AUTOSAR XML (schema 00050)
package /CalDataProvider/ComponentTypes
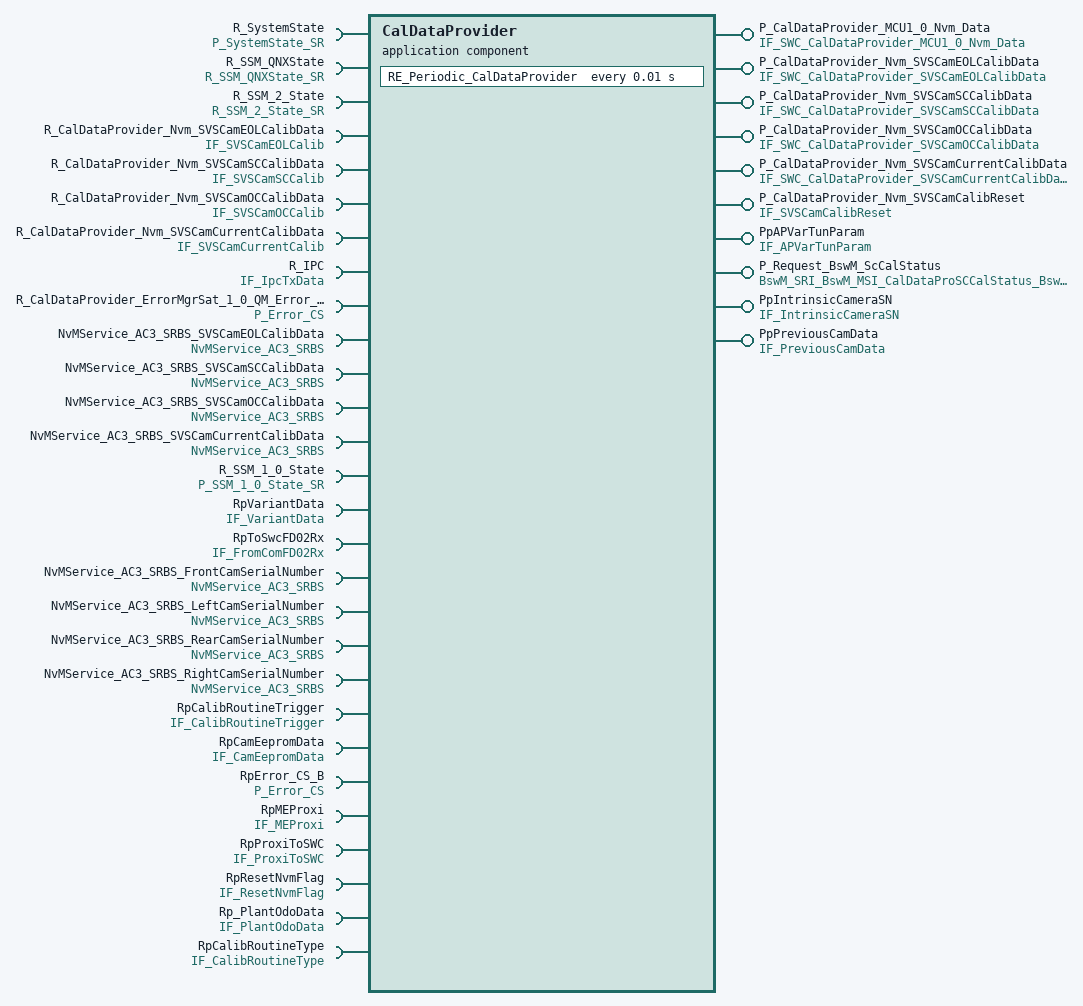
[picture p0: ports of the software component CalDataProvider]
  application sw component type CalDataProvider
    provide port P_CalDataProvider_MCU1_0_Nvm_Data: nonqueued-sender-com-spec{data-element=CalData_mcu1_0, init-value=fields=[{short-label=CalData_SVSCamCurrentCalibData, fields=[{short-label=CamFrontCurrent, fields=[{short-label=CamCalibData_STM, fields=[{short-label=calibdata, fields=[Pitch_f32:0, Yaw_f32:0, Roll_f32:0, CalibStatus_e:0, NewValueAvailable_b:0, OverwriteStatus_b:0]}, X_f32:0, Y_f32:0, Z_f32:0, EOLIterationData_au8:5 x 0, Reserved_au8:7 x 0]}, CamCalibIDs_STM:0]}, {short-label=CamLeftCurrent, fields=[{short-label=CamCalibData_STM, fields=[{short-label=calibdata, fields=[Pitch_f32:0, Yaw_f32:0, Roll_f32:0, CalibStatus_e:0, NewValueAvailable_b:0, OverwriteStatus_b:0]}, X_f32:0, Y_f32:0, Z_f32:0, EOLIterationData_au8:5 x 0, Reserved_au8:7 x 0]}, CamCalibIDs_STM:0]}, {short-label=CamRearCurrent, fields=[{short-label=CamCalibData_STM, fields=[{short-label=calibdata, fields=[Pitch_f32:0, Yaw_f32:0, Roll_f32:0, CalibStatus_e:0, NewValueAvailable_b:0, OverwriteStatus_b:0]}, X_f32:0, Y_f32:0, Z_f32:0, EOLIterationData_au8:5 x 0, Reserved_au8:7 x 0]}, CamCalibIDs_STM:0]}, {short-label=CamRightCurrent, fields=[{short-label=CamCalibData_STM, fields=[{short-label=calibdata, fields=[Pitch_f32:0, Yaw_f32:0, Roll_f32:0, CalibStatus_e:0, NewValueAvailable_b:0, OverwriteStatus_b:0]}, X_f32:0, Y_f32:0, Z_f32:0, EOLIterationData_au8:5 x 0, Reserved_au8:7 x 0]}, CamCalibIDs_STM:0]}]}, {short-label=CalData_SVSCamEOLCalibData, fields=[{short-label=CamFrontEOL, fields=[{short-label=CamCalibData_STM, fields=[{short-label=calibdata, fields=[Pitch_f32:0, Yaw_f32:0, Roll_f32:0, CalibStatus_e:0, NewValueAvailable_b:0, OverwriteStatus_b:0]}, X_f32:0, Y_f32:0, Z_f32:0, EOLIterationData_au8:5 x 0, Reserved_au8:7 x 0]}, CamCalibIDs_STM:0]}, {short-label=CamLeftEOL, fields=[{short-label=CamCalibData_STM, fields=[{short-label=calibdata, fields=[Pitch_f32:0, Yaw_f32:0, Roll_f32:0, CalibStatus_e:0, NewValueAvailable_b:0, OverwriteStatus_b:0]}, X_f32:0, Y_f32:0, Z_f32:0, EOLIterationData_au8:5 x 0, Reserved_au8:7 x 0]}, CamCalibIDs_STM:0]}, {short-label=CamRearEOL, fields=[{short-label=CamCalibData_STM, fields=[{short-label=calibdata, fields=[Pitch_f32:0, Yaw_f32:0, Roll_f32:0, CalibStatus_e:0, NewValueAvailable_b:0, OverwriteStatus_b:0]}, X_f32:0, Y_f32:0, Z_f32:0, EOLIterationData_au8:5 x 0, Reserved_au8:7 x 0]}, CamCalibIDs_STM:0]}, {short-label=CamRightEOL, fields=[{short-label=CamCalibData_STM, fields=[{short-label=calibdata, fields=[Pitch_f32:0, Yaw_f32:0, Roll_f32:0, CalibStatus_e:0, NewValueAvailable_b:0, OverwriteStatus_b:0]}, X_f32:0, Y_f32:0, Z_f32:0, EOLIterationData_au8:5 x 0, Reserved_au8:7 x 0]}, CamCalibIDs_STM:0]}]}, {short-label=CalData_SVSCamOCCalibData, fields=[{short-label=CamFrontOC, fields=[{short-label=CamCalibData_STM, fields=[Pitch_f32:0, Yaw_f32:0, Roll_f32:0, CalibStatus_e:0, NewValueAvailable_b:0, OverwriteStatus_b:0]}, CamCalibIDs_STM:0]}, {short-label=CamLeftOC, fields=[{short-label=CamCalibData_STM, fields=[Pitch_f32:0, Yaw_f32:0, Roll_f32:0, CalibStatus_e:0, NewValueAvailable_b:0, OverwriteStatus_b:0]}, CamCalibIDs_STM:0]}, {short-label=CamRearOC, fields=[{short-label=CamCalibData_STM, fields=[Pitch_f32:0, Yaw_f32:0, Roll_f32:0, CalibStatus_e:0, NewValueAvailable_b:0, OverwriteStatus_b:0]}, CamCalibIDs_STM:0]}, {short-label=CamRightOC, fields=[{short-label=CamCalibData_STM, fields=[Pitch_f32:0, Yaw_f32:0, Roll_f32:0, CalibStatus_e:0, NewValueAvailable_b:0, OverwriteStatus_b:0]}, CamCalibIDs_STM:0]}]}, {short-label=CalData_SVSCamSCCalibData, fields=[{short-label=CamFrontSC, fields=[{short-label=CamCalibData_STM, fields=[Pitch_f32:0, Yaw_f32:0, Roll_f32:0, CalibStatus_e:0, NewValueAvailable_b:0, OverwriteStatus_b:0]}, CamCalibIDs_STM:0]}, {short-label=CamLeftSC, fields=[{short-label=CamCalibData_STM, fields=[Pitch_f32:0, Yaw_f32:0, Roll_f32:0, CalibStatus_e:0, NewValueAvailable_b:0, OverwriteStatus_b:0]}, CamCalibIDs_STM:0]}, {short-label=CamRearSC, fields=[{short-label=CamCalibData_STM, fields=[Pitch_f32:0, Yaw_f32:0, Roll_f32:0, CalibStatus_e:0, NewValueAvailable_b:0, OverwriteStatus_b:0]}, CamCalibIDs_STM:0]}, {short-label=CamRightSC, fields=[{short-label=CamCalibData_STM, fields=[Pitch_f32:0, Yaw_f32:0, Roll_f32:0, CalibStatus_e:0, NewValueAvailable_b:0, OverwriteStatus_b:0]}, CamCalibIDs_STM:0]}]}, FreshnessCount:0, CalData_PlantOdoValue:0, CalData_PrevOdoValue:0, bValid:0]}, provided-interface=IF_SWC_CalDataProvider_MCU1_0_Nvm_Data
    9 x require port:
      R_SystemState: nonqueued-receiver-com-spec=data-element=SystemState, required-interface=P_SystemState_SR
      R_SSM_QNXState: nonqueued-receiver-com-spec=data-element=State_QNX, required-interface=R_SSM_QNXState_SR
      R_SSM_2_State: required-interface=R_SSM_2_State_SR
        required-com-specs:
          data-element=State_2_0, filter=data-filter-type=ALWAYS
          data-element=State_2_1, filter=data-filter-type=ALWAYS
      R_CalDataProvider_Nvm_SVSCamEOLCalibData: nonqueued-receiver-com-spec=data-element=TbSVS_S_SVSCamEOLCalibDataToNVM_t, required-interface=IF_SVSCamEOLCalib
      R_CalDataProvider_Nvm_SVSCamSCCalibData: nonqueued-receiver-com-spec=data-element=TbSVS_S_SVSCamSCCalibDataToNVM_t, required-interface=IF_SVSCamSCCalib
      R_CalDataProvider_Nvm_SVSCamOCCalibData: nonqueued-receiver-com-spec=data-element=TbSVS_S_SVSCamOCCalibDataToNVM_t, required-interface=IF_SVSCamOCCalib
      R_CalDataProvider_Nvm_SVSCamCurrentCalibData: nonqueued-receiver-com-spec=data-element=TbSVS_S_SVSCamCurrentCalibDataToNVM_t, required-interface=IF_SVSCamCurrentCalib
      R_IPC: client-com-spec=IPC_Write_v, required-interface=IF_IpcTxData
      R_CalDataProvider_ErrorMgrSat_1_0_QM_Error_CS: client-com-spec=ReportErrorStatus1_0_QM, required-interface=P_Error_CS
    4 x provide port, all with server-com-spec{operation=WriteBlock, queue-length=1}:
      P_CalDataProvider_Nvm_SVSCamEOLCalibData: provided-interface=IF_SWC_CalDataProvider_SVSCamEOLCalibData
      P_CalDataProvider_Nvm_SVSCamSCCalibData: provided-interface=IF_SWC_CalDataProvider_SVSCamSCCalibData
      P_CalDataProvider_Nvm_SVSCamOCCalibData: provided-interface=IF_SWC_CalDataProvider_SVSCamOCCalibData
      P_CalDataProvider_Nvm_SVSCamCurrentCalibData: provided-interface=IF_SWC_CalDataProvider_SVSCamCurrentCalibData
    5 x require port:
      NvMService_AC3_SRBS_SVSCamEOLCalibData: required-com-specs=[WriteBlock, SetRamBlockStatus, ReadBlock, InvalidateNvBlock, GetErrorStatus, EraseBlock], required-interface=NvMService_AC3_SRBS
      NvMService_AC3_SRBS_SVSCamSCCalibData: required-com-specs=[WriteBlock, SetRamBlockStatus, ReadBlock, InvalidateNvBlock, GetErrorStatus, EraseBlock], required-interface=NvMService_AC3_SRBS
      NvMService_AC3_SRBS_SVSCamOCCalibData: required-com-specs=[WriteBlock, SetRamBlockStatus, ReadBlock, InvalidateNvBlock, GetErrorStatus, EraseBlock], required-interface=NvMService_AC3_SRBS
      NvMService_AC3_SRBS_SVSCamCurrentCalibData: required-com-specs=[WriteBlock, SetRamBlockStatus, ReadBlock, InvalidateNvBlock, GetErrorStatus, EraseBlock], required-interface=NvMService_AC3_SRBS
      R_SSM_1_0_State: nonqueued-receiver-com-spec{data-element=State_1_0, filter=data-filter-type=ALWAYS, init-value=fields=[CoreStatus:0, LocalAppStatus:20 x 0]}, required-interface=P_SSM_1_0_State_SR
    provide port P_CalDataProvider_Nvm_SVSCamCalibReset: server-com-spec{operation=WriteBlock, queue-length=1}, provided-interface=IF_SVSCamCalibReset
    require port RpVariantData: nonqueued-receiver-com-spec{data-element=Variant, filter=data-filter-type=ALWAYS, init-value=constant-reference=init_Variant}, required-interface=IF_VariantData
    provide port PpAPVarTunParam: nonqueued-sender-com-spec{data-element=TbAP_VrntTunParam_t, init-value=fields=[KeAP_degC_OperatingTempThd:0, KeAP_kph_EnblHysThd:0, KeAP_kph_FrntWarnMaxSpdThd:0, KeAP_kph_ParkMnvThd:0, KeAP_kph_PSDOffThd:0, KeAP_kph_PSDOnThd:0, KeAP_kph_RearWarnMaxSpdThd:0, KeAP_kph_USSActiveSpdThd:0, K_e_RAEB_VehicleWidth:0, K_Overlap_Thrsld_RAEB:5 x 0, KeTOS_s_InTurnDbncTm:0, KeTOS_s_StrDrvDbncTm:0, KeTOS_s_TurnExitDbncTm:0, KeTOS_x_InTurnThd:0, KeTOS_x_TurnExitThd:0, keVehParam_m_DistWhlBse:0, Obj_DistTable:5 x 0, Overlap_Thrsld_Switch:0, RAEB_Envelope_Offset:0, RAEB_Lateral_Distance_Notification:0, RAEB_Minimum_Object_Heigh:0, sampling_time:0, keVehParam_e_VehSteerRatioTable:19 x 0, keVehParam_e_StrWhlRatioBrkPnts:19 x 0, keInpAdptr_e_StWhOffset:0, Straight_Driving_Thresold_rads2:0, Steering_Angle_DeadZone_Start:0, Steering_Angle_DeadZone_End:0, KeAP_k_PathSepaMinSpd:0, KeAP_k_PathSepaSpdRampGrd:0, KeAP_k_DetWP_PreviewTime:0, KeAP_k_LatPathDevPGain:0, KeAP_k_LatPathDevIGain:0, KeAP_k_LatPathDevDGain:0, KeAP_k_LatHeadDevPGain:0, KeAP_k_LatHeadDevIGain:0, KeAP_k_LatHeadDevDGain:0, KeAP_k_SteerUpperLimit:0, KeAP_k_SteerLowerLimit:0, KeAP_k_CtrlOutCollDetActivate:0, KeAP_k_CtrlOutRemainDistNA:0, KeAP_k_CtrlOutCollDetCollDistLimit:0, KeAP_k_CtrlOutCollDetRedStopVal:0, KeAP_k_CtrlOutVehSpdMaxSpotStrTime:0, KeAP_k_CtrlOutVehSpdMaxSpotStrRackDevThd:0, KeAP_k_CtrlOutVehSpdMaxSpotSteer:0, KeAP_k_BrakePGain:0, KeAP_k_BrakeIGain:0, KeAP_k_BrakeUpperLimit:0, KeAP_k_BrakeLowerLimit:0, KeAP_k_CtrlOutGearDrive:0, KeAP_k_CtrlOutGearReverse:0, KeAP_k_CtrlOutGearPark:0, KeAP_k_WhlCircum:0, KeAP_cnt_ChimeVolChgAlert:0, KeAP_cnt_FrntChimeDisTimeThd:0, KeAP_cnt_HalfSecChimeAlert:0, KeAP_cnt_LEDBlinkTimeThd:0, KeAP_cnt_VehKeyOnTimeThd:0, KeAP_Cnt_GearFiltTimeThd:0, KeAP_cnt_TimeStep:0, KeAP_cm_ObjPrestFCDistThd:0, KeAP_cm_ObjPrestRCDistThd:0, KeAP_cm_VehicleWidth:0, KeAP_Cnt_GearOverrideTimeThd:0, KeAP_cnt_SwtStuckTimeThd:0, KeAP_s_BSMInterfaceCntTimeout:0, KeAP_s_CamHandshakeDur:0, KeAP_s_EPSInterfaceCntTimeout:0, KeAP_s_GearShiftWaitCntTimeout:0, KeAP_s_MaxStandstillTimeThd:0, KeAP_s_ObjInPathTimeoutDur:0, KeAP_s_PausedPressBtnTimeoutDur:0, KeAP_s_SeekPhaseTimeoutDur:0, KeAP_s_SpdExceedDur:0, KeAP_cnt_SPMBlinkLEDDur:0, KeAP_cm_VehContour_FSL_x:0, KeAP_cm_VehContour_FOL_x:0, KeAP_cm_VehContour_FIL_x:0, KeAP_cm_VehContour_FIR_x:0, KeAP_cm_VehContour_FOR_x:0, KeAP_cm_VehContour_FSR_x:0, KeAP_cm_VehContour_FSL_y:0, KeAP_cm_VehContour_FOL_y:0, KeAP_cm_VehContour_FIL_y:0, KeAP_cm_VehContour_FIR_y:0, KeAP_cm_VehContour_FOR_y:0, KeAP_cm_VehContour_FSR_y:0, KeAP_cm_VehContour_RSR_x:0, KeAP_cm_VehContour_ROR_x:0, KeAP_cm_VehContour_RIR_x:0, KeAP_cm_VehContour_RIL_x:0, KeAP_cm_VehContour_ROL_x:0, KeAP_cm_VehContour_RSL_x:0, KeAP_cm_VehContour_RSR_y:0, KeAP_cm_VehContour_ROR_y:0, KeAP_cm_VehContour_RIR_y:0, KeAP_cm_VehContour_RIL_y:0, KeAP_cm_VehContour_ROL_y:0, KeAP_cm_VehContour_RSL_y:0, KeAP_cm_DistZone1:0, KeAP_cm_DistZone2:0, KeAP_cm_DistZone3:0, KeAP_cm_DistZone4:0, KeAP_cm_DistZone5:0, KeAP_cm_DistZone6:0, KeAP_cnt_DebounceTimeThd:0, KeAP_cm_FrntLongDistAdj:0, KeAP_cm_HalfVehicleWidth:0, KeAP_cm_HookDistOffset:0, KeAP_cm_MaxNoObjDetctDist:0, KeAP_cm_RearLongDistAdj:0, KeAP_cm_WarnOffset:0, KeAP_e_GbTypAT:0, KeAP_pct_ObjConfidenceThd:0, Reverse_Gr_num:0, KeAP_b_AutoParkEn:0, KeAP_b_FPAEn:0, KeAP_b_FullAutoPark:0, KeAP_b_HookConnected:0, KeAP_b_RPAwithBrk:0, KeAP_b_RPAwithSurroundView:0, KeAP_b_SteerOnlyAutoPark:0, KeCMbB_b_EnblOncObjDbnc:0, dummy:0, dummy1:0, dummy2:0]}, provided-interface=IF_APVarTunParam
    13 x require port:
      RpToSwcFD02Rx: required-interface=IF_FromComFD02Rx
        required-com-specs:
          data-element=Altitude_RMSE_C2, filter=data-filter-type=ALWAYS, init-value=255
          data-element=Battery_Volt_1, filter=data-filter-type=ALWAYS, init-value=0
          data-element=BSM_THA_Brk_Resp, filter=data-filter-type=ALWAYS, init-value=0
          data-element=CurrentCanNMState_FD01_BCM, filter=data-filter-type=ALWAYS, init-value=0
          data-element=CurrentCanNMState_FD01_SGW, filter=data-filter-type=ALWAYS, init-value=0
          data-element=CurrentCanNMState_FD02_BCM, filter=data-filter-type=ALWAYS, init-value=0
          data-element=CurrentCanNMState_FD02_BSM2, filter=data-filter-type=ALWAYS, init-value=0
          data-element=CurrentCanNMState_FD02_CADM2, filter=data-filter-type=ALWAYS, init-value=0
          data-element=CurrentCanNMState_FD02_EPS, filter=data-filter-type=ALWAYS, init-value=0
          data-element=CurrentCanNMState_FD02_ORC, filter=data-filter-type=ALWAYS, init-value=0
          data-element=CurrentCanNMState_FD02_SGW, filter=data-filter-type=ALWAYS, init-value=0
          data-element=CurrentCanNMState_FD02_TRLR_REV, filter=data-filter-type=ALWAYS, init-value=0
          data-element=CurrentCanNMState_FD03_BCM, filter=data-filter-type=ALWAYS, init-value=0
          data-element=CurrentCanNMState_FD03_SGW, filter=data-filter-type=ALWAYS, init-value=0
          data-element=CurrentCanNMState_FD04_BCM, filter=data-filter-type=ALWAYS, init-value=0
          data-element=CurrentCanNMState_FD08_SGW, filter=data-filter-type=ALWAYS, init-value=0
          data-element=CurrentCanNMState_FD11_SGW, filter=data-filter-type=ALWAYS, init-value=0
          data-element=CurrentFailSts_FD01_BCM, filter=data-filter-type=ALWAYS, init-value=0
          data-element=CurrentFailSts_FD01_SGW, filter=data-filter-type=ALWAYS, init-value=0
          data-element=CurrentFailSts_FD02_BCM, filter=data-filter-type=ALWAYS, init-value=0
          data-element=CurrentFailSts_FD02_BSM2, filter=data-filter-type=ALWAYS, init-value=0
          data-element=CurrentFailSts_FD02_CADM2, filter=data-filter-type=ALWAYS, init-value=0
          data-element=CurrentFailSts_FD02_EPS, filter=data-filter-type=ALWAYS, init-value=0
          data-element=CurrentFailSts_FD02_ORC, filter=data-filter-type=ALWAYS, init-value=0
          data-element=CurrentFailSts_FD02_SGW, filter=data-filter-type=ALWAYS, init-value=0
          data-element=CurrentFailSts_FD02_TRLR_REV, filter=data-filter-type=ALWAYS, init-value=0
          data-element=CurrentFailSts_FD03_BCM, filter=data-filter-type=ALWAYS, init-value=0
          data-element=CurrentFailSts_FD03_SGW, filter=data-filter-type=ALWAYS, init-value=0
          data-element=CurrentFailSts_FD04_BCM, filter=data-filter-type=ALWAYS, init-value=0
          data-element=CurrentFailSts_FD08_SGW, filter=data-filter-type=ALWAYS, init-value=0
          data-element=CurrentFailSts_FD11_SGW, filter=data-filter-type=ALWAYS, init-value=0
          data-element=DeltaTimestamp_IMUdata, filter=data-filter-type=ALWAYS, init-value=255
          data-element=DES_FD01_BCM, filter=data-filter-type=ALWAYS, init-value=0
          data-element=DES_FD01_SGW, filter=data-filter-type=ALWAYS, init-value=0
          data-element=DES_FD02_BCM, filter=data-filter-type=ALWAYS, init-value=0
          data-element=DES_FD02_BSM2, filter=data-filter-type=ALWAYS, init-value=0
          data-element=DES_FD02_CADM2, filter=data-filter-type=ALWAYS, init-value=0
          data-element=DES_FD02_EPS, filter=data-filter-type=ALWAYS, init-value=0
          data-element=DES_FD02_ORC, filter=data-filter-type=ALWAYS, init-value=0
          data-element=DES_FD02_SGW, filter=data-filter-type=ALWAYS, init-value=0
          data-element=DES_FD02_TRLR_REV, filter=data-filter-type=ALWAYS, init-value=0
          data-element=DES_FD03_BCM, filter=data-filter-type=ALWAYS, init-value=0
          data-element=DES_FD03_SGW, filter=data-filter-type=ALWAYS, init-value=0
          data-element=DES_FD04_BCM, filter=data-filter-type=ALWAYS, init-value=0
          data-element=DES_FD08_SGW, filter=data-filter-type=ALWAYS, init-value=0
          data-element=DES_FD11_SGW, filter=data-filter-type=ALWAYS, init-value=0
          data-element=Digit_{01..11}, filter=data-filter-type=ALWAYS, init-value=0
          data-element=EOL_FD01_BCM, filter=data-filter-type=ALWAYS, init-value=0
          data-element=EOL_FD01_SGW, filter=data-filter-type=ALWAYS, init-value=0
          data-element=EOL_FD02_BCM, filter=data-filter-type=ALWAYS, init-value=0
          data-element=EOL_FD02_BSM2, filter=data-filter-type=ALWAYS, init-value=0
          data-element=EOL_FD02_CADM2, filter=data-filter-type=ALWAYS, init-value=0
          data-element=EOL_FD02_EPS, filter=data-filter-type=ALWAYS, init-value=0
          data-element=EOL_FD02_ORC, filter=data-filter-type=ALWAYS, init-value=0
          data-element=EOL_FD02_SGW, filter=data-filter-type=ALWAYS, init-value=0
          data-element=EOL_FD02_TRLR_REV, filter=data-filter-type=ALWAYS, init-value=0
          data-element=EOL_FD03_BCM, filter=data-filter-type=ALWAYS, init-value=0
          data-element=EOL_FD03_SGW, filter=data-filter-type=ALWAYS, init-value=0
          data-element=EOL_FD04_BCM, filter=data-filter-type=ALWAYS, init-value=0
          data-element=EOL_FD08_SGW, filter=data-filter-type=ALWAYS, init-value=0
          data-element=EOL_FD11_SGW, filter=data-filter-type=ALWAYS, init-value=0
          data-element=EPBSts, filter=data-filter-type=ALWAYS, init-value=0
          data-element=GenericFailSts_FD01_BCM, filter=data-filter-type=ALWAYS, init-value=0
          data-element=GenericFailSts_FD01_SGW, filter=data-filter-type=ALWAYS, init-value=0
          data-element=GenericFailSts_FD02_BCM, filter=data-filter-type=ALWAYS, init-value=0
          data-element=GenericFailSts_FD02_BSM2, filter=data-filter-type=ALWAYS, init-value=0
          data-element=GenericFailSts_FD02_CADM2, filter=data-filter-type=ALWAYS, init-value=0
          data-element=GenericFailSts_FD02_EPS, filter=data-filter-type=ALWAYS, init-value=0
          data-element=GenericFailSts_FD02_ORC, filter=data-filter-type=ALWAYS, init-value=0
          data-element=GenericFailSts_FD02_SGW, filter=data-filter-type=ALWAYS, init-value=0
          data-element=GenericFailSts_FD02_TRLR_REV, filter=data-filter-type=ALWAYS, init-value=0
          data-element=GenericFailSts_FD03_BCM, filter=data-filter-type=ALWAYS, init-value=0
          data-element=GenericFailSts_FD03_SGW, filter=data-filter-type=ALWAYS, init-value=0
          data-element=GenericFailSts_FD04_BCM, filter=data-filter-type=ALWAYS, init-value=0
          data-element=GenericFailSts_FD08_SGW, filter=data-filter-type=ALWAYS, init-value=0
          data-element=GenericFailSts_FD11_SGW, filter=data-filter-type=ALWAYS, init-value=0
          data-element=Heading_Angle_C2, filter=data-filter-type=ALWAYS, init-value=65535
          data-element=IgnitionOnCounter, filter=data-filter-type=ALWAYS, init-value=0
          data-element=LatAcceleration_C2, filter=data-filter-type=ALWAYS, init-value=4095
          data-element=LatAccelerationOffset_BSM, filter=data-filter-type=ALWAYS, init-value=255
          data-element=Latitude_RMSE_C2, filter=data-filter-type=ALWAYS, init-value=255
          data-element=LHF_FastPulseCounter, filter=data-filter-type=ALWAYS, init-value=0
          data-element=LHF_Spin, filter=data-filter-type=ALWAYS, init-value=0
          data-element=LHFWheelSpeed, filter=data-filter-type=ALWAYS, init-value=0
          data-element=LHR_FastPulseCounter, filter=data-filter-type=ALWAYS, init-value=0
          data-element=LHR_Spin, filter=data-filter-type=ALWAYS, init-value=0
          data-element=LHRWheelSpeed, filter=data-filter-type=ALWAYS, init-value=0
          data-element=LongAcceleration_C2, filter=data-filter-type=ALWAYS, init-value=4095
          data-element=LongAccelerationOffset_BSM, filter=data-filter-type=ALWAYS, init-value=255
          data-element=Longitude_RMSE_C2, filter=data-filter-type=ALWAYS, init-value=255
          data-element=OperationalModeSts, filter=data-filter-type=ALWAYS, init-value=0
          data-element=Pitch_RMSE_C2, filter=data-filter-type=ALWAYS, init-value=255
          data-element=PitchRate_C2, filter=data-filter-type=ALWAYS, init-value=4095
          data-element=PreviousCanNMState_FD01_BCM, filter=data-filter-type=ALWAYS, init-value=0
          data-element=PreviousCanNMState_FD01_SGW, filter=data-filter-type=ALWAYS, init-value=0
          data-element=PreviousCanNMState_FD02_BCM, filter=data-filter-type=ALWAYS, init-value=0
          data-element=PreviousCanNMState_FD02_BSM2, filter=data-filter-type=ALWAYS, init-value=0
          data-element=PreviousCanNMState_FD02_CADM2, filter=data-filter-type=ALWAYS, init-value=0
          data-element=PreviousCanNMState_FD02_EPS, filter=data-filter-type=ALWAYS, init-value=0
          data-element=PreviousCanNMState_FD02_ORC, filter=data-filter-type=ALWAYS, init-value=0
          data-element=PreviousCanNMState_FD02_SGW, filter=data-filter-type=ALWAYS, init-value=0
          data-element=PreviousCanNMState_FD02_TRLR_REV, filter=data-filter-type=ALWAYS, init-value=0
          data-element=PreviousCanNMState_FD03_BCM, filter=data-filter-type=ALWAYS, init-value=0
          data-element=PreviousCanNMState_FD03_SGW, filter=data-filter-type=ALWAYS, init-value=0
          data-element=PreviousCanNMState_FD04_BCM, filter=data-filter-type=ALWAYS, init-value=0
          data-element=PreviousCanNMState_FD08_SGW, filter=data-filter-type=ALWAYS, init-value=0
          data-element=PreviousCanNMState_FD11_SGW, filter=data-filter-type=ALWAYS, init-value=0
          data-element=REF_VEH_SPEED, filter=data-filter-type=ALWAYS, init-value=1023
          data-element=RemStActvSts, filter=data-filter-type=ALWAYS, init-value=0
          data-element=RHF_FastPulseCounter, filter=data-filter-type=ALWAYS, init-value=0
          data-element=RHF_Spin, filter=data-filter-type=ALWAYS, init-value=0
          data-element=RHFWheelSpeed, filter=data-filter-type=ALWAYS, init-value=0
          data-element=RHR_FastPulseCounter, filter=data-filter-type=ALWAYS, init-value=0
          data-element=RHR_Spin, filter=data-filter-type=ALWAYS, init-value=0
          data-element=RHRWheelSpeed, filter=data-filter-type=ALWAYS, init-value=0
          data-element=Roll_RMSE_C2, filter=data-filter-type=ALWAYS, init-value=255
          data-element=RollRate_C2, filter=data-filter-type=ALWAYS, init-value=4095
          data-element=SBR1RowDriverSeatSts, filter=data-filter-type=ALWAYS, init-value=3
          data-element=StayActiveSource_FD01_BCM, filter=data-filter-type=ALWAYS, init-value=0
          data-element=StayActiveSource_FD01_SGW, filter=data-filter-type=ALWAYS, init-value=0
          data-element=StayActiveSource_FD02_BCM, filter=data-filter-type=ALWAYS, init-value=0
          data-element=StayActiveSource_FD02_BSM2, filter=data-filter-type=ALWAYS, init-value=0
          data-element=StayActiveSource_FD02_CADM2, filter=data-filter-type=ALWAYS, init-value=0
          data-element=StayActiveSource_FD02_EPS, filter=data-filter-type=ALWAYS, init-value=0
          data-element=StayActiveSource_FD02_ORC, filter=data-filter-type=ALWAYS, init-value=0
          data-element=StayActiveSource_FD02_SGW, filter=data-filter-type=ALWAYS, init-value=0
          data-element=StayActiveSource_FD02_TRLR_REV, filter=data-filter-type=ALWAYS, init-value=0
          data-element=StayActiveSource_FD03_BCM, filter=data-filter-type=ALWAYS, init-value=0
          data-element=StayActiveSource_FD03_SGW, filter=data-filter-type=ALWAYS, init-value=0
          data-element=StayActiveSource_FD04_BCM, filter=data-filter-type=ALWAYS, init-value=0
          data-element=StayActiveSource_FD08_SGW, filter=data-filter-type=ALWAYS, init-value=0
          data-element=StayActiveSource_FD11_SGW, filter=data-filter-type=ALWAYS, init-value=0
          data-element=TotalOdometer, filter=data-filter-type=ALWAYS, init-value=0
          data-element=TRSC_CenterBtn_Sts, filter=data-filter-type=ALWAYS, init-value=0
          data-element=TRSC_EnableBtn_Sts, filter=data-filter-type=ALWAYS, init-value=0
          data-element=TRSC_RawKnob, filter=data-filter-type=ALWAYS, init-value=0
          data-element=TurnIndicatorSts, filter=data-filter-type=ALWAYS, init-value=0
          data-element=VehicleStandStillSts, filter=data-filter-type=ALWAYS, init-value=1
          data-element=VerticalAcceleration_C2, filter=data-filter-type=ALWAYS, init-value=4095
          data-element=WakeupSource_FD01_ADCM, filter=data-filter-type=ALWAYS, init-value=0
          data-element=WakeupSource_FD01_BCM, filter=data-filter-type=ALWAYS, init-value=0
          data-element=WakeupSource_FD01_SGW, filter=data-filter-type=ALWAYS, init-value=0
          data-element=WakeupSource_FD02_BCM, filter=data-filter-type=ALWAYS, init-value=0
          data-element=WakeupSource_FD02_BSM2, filter=data-filter-type=ALWAYS, init-value=0
          data-element=WakeupSource_FD02_CADM2, filter=data-filter-type=ALWAYS, init-value=0
          data-element=WakeupSource_FD02_EPS, filter=data-filter-type=ALWAYS, init-value=0
          data-element=WakeupSource_FD02_ORC, filter=data-filter-type=ALWAYS, init-value=0
          data-element=WakeupSource_FD02_SGW, filter=data-filter-type=ALWAYS, init-value=0
          data-element=WakeupSource_FD02_TRLR_REV, filter=data-filter-type=ALWAYS, init-value=0
          data-element=WakeupSource_FD03_BCM, filter=data-filter-type=ALWAYS, init-value=0
          data-element=WakeupSource_FD03_SGW, filter=data-filter-type=ALWAYS, init-value=0
          data-element=WakeupSource_FD04_BCM, filter=data-filter-type=ALWAYS, init-value=0
          data-element=WakeupSource_FD08_SGW, filter=data-filter-type=ALWAYS, init-value=0
          data-element=WakeupSource_FD11_SGW, filter=data-filter-type=ALWAYS, init-value=0
          data-element=YawRate_C2, filter=data-filter-type=ALWAYS, init-value=4095
          data-element=YawRate_RMSE_C2, filter=data-filter-type=ALWAYS, init-value=255
      NvMService_AC3_SRBS_FrontCamSerialNumber: required-com-specs=[WriteBlock, SetRamBlockStatus, ReadBlock, InvalidateNvBlock, GetErrorStatus, EraseBlock], required-interface=NvMService_AC3_SRBS
      NvMService_AC3_SRBS_LeftCamSerialNumber: required-com-specs=[WriteBlock, SetRamBlockStatus, ReadBlock, InvalidateNvBlock, GetErrorStatus, EraseBlock], required-interface=NvMService_AC3_SRBS
      NvMService_AC3_SRBS_RearCamSerialNumber: required-com-specs=[WriteBlock, SetRamBlockStatus, ReadBlock, InvalidateNvBlock, GetErrorStatus, EraseBlock], required-interface=NvMService_AC3_SRBS
      NvMService_AC3_SRBS_RightCamSerialNumber: required-com-specs=[WriteBlock, SetRamBlockStatus, ReadBlock, InvalidateNvBlock, GetErrorStatus, EraseBlock], required-interface=NvMService_AC3_SRBS
      RpCalibRoutineTrigger: nonqueued-receiver-com-spec{data-element=routine_b, filter=data-filter-type=ALWAYS, init-value=0}, required-interface=IF_CalibRoutineTrigger
      RpCamEepromData: nonqueued-receiver-com-spec{data-element=Svs_CamEepromDataArray_t, filter=data-filter-type=ALWAYS}, required-interface=IF_CamEepromData
      RpError_CS_B: client-com-spec=ReportErrorStatus1_0_B, required-interface=P_Error_CS
      RpMEProxi: nonqueued-receiver-com-spec{data-element=ME_Proxi_MPU1_0_to_MCU1_0_t, filter=data-filter-type=ALWAYS}, required-interface=IF_MEProxi
      RpProxiToSWC: required-interface=IF_ProxiToSWC
        required-com-specs:
          data-element=TyreSz_u16, filter=data-filter-type=ALWAYS
          data-element=SurroundViewCam_u8, filter=data-filter-type=ALWAYS
          data-element=Fullautomaticparking, filter=data-filter-type=ALWAYS
          data-element=PRX_CanNod27_b, filter=data-filter-type=ALWAYS
          data-element=Parkwithstop_u8, filter=data-filter-type=ALWAYS
          data-element=Trailerhitchassist_u8, filter=data-filter-type=ALWAYS
          data-element=PAMConfig_u8, filter=data-filter-type=ALWAYS
          data-element=Pamtuningset, filter=data-filter-type=ALWAYS
      RpResetNvmFlag: nonqueued-receiver-com-spec{data-element=V_ResetNvmFlag_b, filter=data-filter-type=ALWAYS}, required-interface=IF_ResetNvmFlag
      Rp_PlantOdoData: nonqueued-receiver-com-spec{data-element=PlantOdoData, filter=data-filter-type=ALWAYS, init-value=0}, required-interface=IF_PlantOdoData
      RpCalibRoutineType: nonqueued-receiver-com-spec{data-element=value, filter=data-filter-type=ALWAYS, init-value=0}, required-interface=IF_CalibRoutineType
    provide port P_Request_BswM_ScCalStatus: nonqueued-sender-com-spec=requestedMode, provided-interface=BswM_SRI_BswM_MSI_CalDataProSCCalStatus_BswM_MDGP_CalDataProSCCalStatus
    provide port PpIntrinsicCameraSN: server-com-spec{operation=Readblock, queue-length=1}, provided-interface=IF_IntrinsicCameraSN
    provide port PpPreviousCamData: nonqueued-sender-com-spec{data-element=Data, init-value=fields=[calibrated:0, {short-label=data, fields=[{short-label=CamFrontCurrent, fields=[{short-label=CamCalibData_STM, fields=[{short-label=calibdata, fields=[Pitch_f32:0, Yaw_f32:0, Roll_f32:0, CalibStatus_e:0, NewValueAvailable_b:0, OverwriteStatus_b:0]}, X_f32:0, Y_f32:0, Z_f32:0, EOLIterationData_au8:5 x 0, Reserved_au8:7 x 0]}, CamCalibIDs_STM:0]}, {short-label=CamLeftCurrent, fields=[{short-label=CamCalibData_STM, fields=[{short-label=calibdata, fields=[Pitch_f32:0, Yaw_f32:0, Roll_f32:0, CalibStatus_e:0, NewValueAvailable_b:0, OverwriteStatus_b:0]}, X_f32:0, Y_f32:0, Z_f32:0, EOLIterationData_au8:5 x 0, Reserved_au8:7 x 0]}, CamCalibIDs_STM:0]}, {short-label=CamRearCurrent, fields=[{short-label=CamCalibData_STM, fields=[{short-label=calibdata, fields=[Pitch_f32:0, Yaw_f32:0, Roll_f32:0, CalibStatus_e:0, NewValueAvailable_b:0, OverwriteStatus_b:0]}, X_f32:0, Y_f32:0, Z_f32:0, EOLIterationData_au8:5 x 0, Reserved_au8:7 x 0]}, CamCalibIDs_STM:0]}, {short-label=CamRightCurrent, fields=[{short-label=CamCalibData_STM, fields=[{short-label=calibdata, fields=[Pitch_f32:0, Yaw_f32:0, Roll_f32:0, CalibStatus_e:0, NewValueAvailable_b:0, OverwriteStatus_b:0]}, X_f32:0, Y_f32:0, Z_f32:0, EOLIterationData_au8:5 x 0, Reserved_au8:7 x 0]}, CamCalibIDs_STM:0]}]}, PrevOdoValue:0]}, provided-interface=IF_PreviousCamData
    behavior CalDataProvider_InternalBehavior: data-type-mapping=DataTypeMappings_DEV, handle-termination-and-restart=NO-SUPPORT
      ar-typed-per-instance-memorys:
        8 x data, all with sw-calibration-access=READ-ONLY:
          SVSCamEOLCalibData_MirrorBlock: type=CDP_TbSVS_S_SVSCamEOLCalibData_t
          SVSCamSCCalibData_MirrorBlock: type=CDP_TbSVS_S_SVSCamSCCalibData_t
          SVSCamOCCalibData_MirrorBlock: type=CDP_TbSVS_S_SVSCamOCCalibData_t
          SVSCamCurrentCalibData_MirrorBlock: type=CDP_TbSVS_S_SVSCamCurrentCalibData_t
          FrontCamSerialNumber_MirrorBlock: type=FinalAssemblySerialNumber_t
          LeftCamSerialNumber_MirrorBlock: type=FinalAssemblySerialNumber_t
          RearCamSerialNumber_MirrorBlock: type=FinalAssemblySerialNumber_t
          RightCamSerialNumber_MirrorBlock: type=FinalAssemblySerialNumber_t
      timing event TMT_RE_Periodic_CalDataProvider: start-on-event=RE_Periodic_CalDataProvider, period=0.01
      init event InitEvent: start-on-event=RE_CalDataProvider_Init
      6 x operation invoked event:
        OIT_RE_P_CalDataProvider_Nvm_SVSCamSCCalibData_WriteBlock_P_CalDataProvider_Nvm_SVSCamSCCalibData_WriteBlock: start-on-event=RE_CalDataProvider_Nvm_SVSCamSCCalibData_WriteBlock, operation=P_CalDataProvider_Nvm_SVSCamSCCalibData.WriteBlock
        OIT_RE_P_CalDataProvider_Nvm_SVSCamOCCalibData_WriteBlock_P_CalDataProvider_Nvm_SVSCamOCCalibData_WriteBlock: start-on-event=RE_CalDataProvider_Nvm_SVSCamOCCalibData_WriteBlock, operation=P_CalDataProvider_Nvm_SVSCamOCCalibData.WriteBlock
        OIT_RE_P_CalDataProvider_Nvm_SVSCamCurrentCalibData_WriteBlock_P_CalDataProvider_Nvm_SVSCamCurrentCalibData_WriteBlock: start-on-event=RE_CalDataProvider_Nvm_SVSCamCurrentCalibData_WriteBlock, operation=P_CalDataProvider_Nvm_SVSCamCurrentCalibData.WriteBlock
        OIT_RE_P_CalDataProvider_Nvm_SVSCamEOLCalibData_WriteBlock_P_CalDataProvider_Nvm_SVSCamEOLCalibData_WriteBlock: start-on-event=RE_CalDataProvider_Nvm_SVSCamEOLCalibData_WriteBlock, operation=P_CalDataProvider_Nvm_SVSCamEOLCalibData.WriteBlock
        OIT_RE_P_SVSCamCalibReset_WriteBlock_P_SVSCamCalibReset_WriteBlock: start-on-event=RE_CalDataProvider_Nvm_SVSCamCalibReset, operation=P_CalDataProvider_Nvm_SVSCamCalibReset.WriteBlock
        OIT_PpIntrinsicCameraSN_Readblock_PpIntrinsicCameraSN_Readblock: start-on-event=RE_IntrinsicCameraSN_Readblock, operation=PpIntrinsicCameraSN.Readblock
      per-instance-parameters:
        8 x parameter data prototype, all with sw-calibration-access=READ-WRITE:
          SVSCamEOLCalibData_DefaultValue: type=CDP_TbSVS_S_SVSCamEOLCalibData_t, init-value=fields=[calibrated:0, {short-label=data, fields=[{short-label=CamFrontEOL, fields=[{short-label=CamCalibData_STM, fields=[{short-label=calibdata, fields=[Pitch_f32:0, Yaw_f32:0, Roll_f32:0, CalibStatus_e:0, NewValueAvailable_b:0, OverwriteStatus_b:0]}, X_f32:0, Y_f32:0, Z_f32:0, EOLIterationData_au8:5 x 0, Reserved_au8:7 x 0]}, CamCalibIDs_STM:0]}, {short-label=CamLeftEOL, fields=[{short-label=CamCalibData_STM, fields=[{short-label=calibdata, fields=[Pitch_f32:0, Yaw_f32:0, Roll_f32:0, CalibStatus_e:0, NewValueAvailable_b:0, OverwriteStatus_b:0]}, X_f32:0, Y_f32:0, Z_f32:0, EOLIterationData_au8:5 x 0, Reserved_au8:7 x 0]}, CamCalibIDs_STM:0]}, {short-label=CamRearEOL, fields=[{short-label=CamCalibData_STM, fields=[{short-label=calibdata, fields=[Pitch_f32:0, Yaw_f32:0, Roll_f32:0, CalibStatus_e:0, NewValueAvailable_b:0, OverwriteStatus_b:0]}, X_f32:0, Y_f32:0, Z_f32:0, EOLIterationData_au8:5 x 0, Reserved_au8:7 x 0]}, CamCalibIDs_STM:0]}, {short-label=CamRightEOL, fields=[{short-label=CamCalibData_STM, fields=[{short-label=calibdata, fields=[Pitch_f32:0, Yaw_f32:0, Roll_f32:0, CalibStatus_e:0, NewValueAvailable_b:0, OverwriteStatus_b:0]}, X_f32:0, Y_f32:0, Z_f32:0, EOLIterationData_au8:5 x 0, Reserved_au8:7 x 0]}, CamCalibIDs_STM:0]}]}, PlantOdoValue:0]
          SVSCamSCCalibData_DefaultValue: type=CDP_TbSVS_S_SVSCamSCCalibData_t, init-value=fields=[calibrated:0, {short-label=data, fields=[{short-label=CamFrontSC, fields=[{short-label=CamCalibData_STM, fields=[Pitch_f32:0, Yaw_f32:0, Roll_f32:0, CalibStatus_e:0, NewValueAvailable_b:0, OverwriteStatus_b:0]}, CamCalibIDs_STM:0]}, {short-label=CamLeftSC, fields=[{short-label=CamCalibData_STM, fields=[Pitch_f32:0, Yaw_f32:0, Roll_f32:0, CalibStatus_e:0, NewValueAvailable_b:0, OverwriteStatus_b:0]}, CamCalibIDs_STM:0]}, {short-label=CamRearSC, fields=[{short-label=CamCalibData_STM, fields=[Pitch_f32:0, Yaw_f32:0, Roll_f32:0, CalibStatus_e:0, NewValueAvailable_b:0, OverwriteStatus_b:0]}, CamCalibIDs_STM:0]}, {short-label=CamRightSC, fields=[{short-label=CamCalibData_STM, fields=[Pitch_f32:0, Yaw_f32:0, Roll_f32:0, CalibStatus_e:0, NewValueAvailable_b:0, OverwriteStatus_b:0]}, CamCalibIDs_STM:0]}]}]
          SVSCamOCCalibData_DefaultValue: type=CDP_TbSVS_S_SVSCamOCCalibData_t, init-value=fields=[calibrated:0, {short-label=data, fields=[{short-label=CamFrontOC, fields=[{short-label=CamCalibData_STM, fields=[Pitch_f32:0, Yaw_f32:0, Roll_f32:0, CalibStatus_e:0, NewValueAvailable_b:0, OverwriteStatus_b:0]}, CamCalibIDs_STM:0]}, {short-label=CamLeftOC, fields=[{short-label=CamCalibData_STM, fields=[Pitch_f32:0, Yaw_f32:0, Roll_f32:0, CalibStatus_e:0, NewValueAvailable_b:0, OverwriteStatus_b:0]}, CamCalibIDs_STM:0]}, {short-label=CamRearOC, fields=[{short-label=CamCalibData_STM, fields=[Pitch_f32:0, Yaw_f32:0, Roll_f32:0, CalibStatus_e:0, NewValueAvailable_b:0, OverwriteStatus_b:0]}, CamCalibIDs_STM:0]}, {short-label=CamRightOC, fields=[{short-label=CamCalibData_STM, fields=[Pitch_f32:0, Yaw_f32:0, Roll_f32:0, CalibStatus_e:0, NewValueAvailable_b:0, OverwriteStatus_b:0]}, CamCalibIDs_STM:0]}]}]
          SVSCamCurrentCalibData_DefaultValue: type=CDP_TbSVS_S_SVSCamCurrentCalibData_t, init-value=fields=[calibrated:0, {short-label=data, fields=[{short-label=CamFrontCurrent, fields=[{short-label=CamCalibData_STM, fields=[{short-label=calibdata, fields=[Pitch_f32:0, Yaw_f32:0, Roll_f32:0, CalibStatus_e:0, NewValueAvailable_b:0, OverwriteStatus_b:0]}, X_f32:0, Y_f32:0, Z_f32:0, EOLIterationData_au8:5 x 0, Reserved_au8:7 x 0]}, CamCalibIDs_STM:0]}, {short-label=CamLeftCurrent, fields=[{short-label=CamCalibData_STM, fields=[{short-label=calibdata, fields=[Pitch_f32:0, Yaw_f32:0, Roll_f32:0, CalibStatus_e:0, NewValueAvailable_b:0, OverwriteStatus_b:0]}, X_f32:0, Y_f32:0, Z_f32:0, EOLIterationData_au8:5 x 0, Reserved_au8:7 x 0]}, CamCalibIDs_STM:0]}, {short-label=CamRearCurrent, fields=[{short-label=CamCalibData_STM, fields=[{short-label=calibdata, fields=[Pitch_f32:0, Yaw_f32:0, Roll_f32:0, CalibStatus_e:0, NewValueAvailable_b:0, OverwriteStatus_b:0]}, X_f32:0, Y_f32:0, Z_f32:0, EOLIterationData_au8:5 x 0, Reserved_au8:7 x 0]}, CamCalibIDs_STM:0]}, {short-label=CamRightCurrent, fields=[{short-label=CamCalibData_STM, fields=[{short-label=calibdata, fields=[Pitch_f32:0, Yaw_f32:0, Roll_f32:0, CalibStatus_e:0, NewValueAvailable_b:0, OverwriteStatus_b:0]}, X_f32:0, Y_f32:0, Z_f32:0, EOLIterationData_au8:5 x 0, Reserved_au8:7 x 0]}, CamCalibIDs_STM:0]}]}, PrevOdoValue:0]
          FrontCamSerialNumber_DefaultValue: type=FinalAssemblySerialNumber_t, init-value=fields=[finalAssemblyYear:[0, 0], finalAssemblyDay:[0, 0, 0], finalAssemblySerialNumber:[0, 0, 0, 0], finalAssemblyFocusAndAlign:[0]]
          LeftCamSerialNumber_DefaultValue: type=FinalAssemblySerialNumber_t, init-value=fields=[finalAssemblyYear:[0, 0], finalAssemblyDay:[0, 0, 0], finalAssemblySerialNumber:[0, 0, 0, 0], finalAssemblyFocusAndAlign:[0]]
          RearCamSerialNumber_DefaultValue: type=FinalAssemblySerialNumber_t, init-value=fields=[finalAssemblyYear:[0, 0], finalAssemblyDay:[0, 0, 0], finalAssemblySerialNumber:[0, 0, 0, 0], finalAssemblyFocusAndAlign:[0]]
          RightCamSerialNumber_DefaultValue: type=FinalAssemblySerialNumber_t, init-value=fields=[finalAssemblyYear:[0, 0], finalAssemblyDay:[0, 0, 0], finalAssemblySerialNumber:[0, 0, 0, 0], finalAssemblyFocusAndAlign:[0]]
      port-api-options:
        enable-take-address=false, error-handling=NO-TRANSFORMER-ERROR-HANDLING, indirect-api=false, port=P_CalDataProvider_MCU1_0_Nvm_Data
        enable-take-address=false, error-handling=NO-TRANSFORMER-ERROR-HANDLING, indirect-api=false, port=R_CalDataProvider_ErrorMgrSat_1_0_QM_Error_CS
        enable-take-address=false, error-handling=NO-TRANSFORMER-ERROR-HANDLING, indirect-api=false, port=R_CalDataProvider_Nvm_SVSCamCurrentCalibData
        enable-take-address=false, error-handling=NO-TRANSFORMER-ERROR-HANDLING, indirect-api=false, port=R_CalDataProvider_Nvm_SVSCamEOLCalibData
        enable-take-address=false, error-handling=NO-TRANSFORMER-ERROR-HANDLING, indirect-api=false, port=R_CalDataProvider_Nvm_SVSCamOCCalibData
        enable-take-address=false, error-handling=NO-TRANSFORMER-ERROR-HANDLING, indirect-api=false, port=R_CalDataProvider_Nvm_SVSCamSCCalibData
        enable-take-address=false, error-handling=NO-TRANSFORMER-ERROR-HANDLING, indirect-api=false, port=R_IPC
        enable-take-address=false, error-handling=NO-TRANSFORMER-ERROR-HANDLING, indirect-api=false, port=R_SSM_2_State
        enable-take-address=false, error-handling=NO-TRANSFORMER-ERROR-HANDLING, indirect-api=false, port=R_SSM_QNXState
        enable-take-address=false, error-handling=NO-TRANSFORMER-ERROR-HANDLING, indirect-api=false, port=R_SystemState
        enable-take-address=false, error-handling=NO-TRANSFORMER-ERROR-HANDLING, indirect-api=false, port=P_CalDataProvider_Nvm_SVSCamCurrentCalibData
        enable-take-address=false, error-handling=NO-TRANSFORMER-ERROR-HANDLING, indirect-api=false, port=P_CalDataProvider_Nvm_SVSCamEOLCalibData
        enable-take-address=false, error-handling=NO-TRANSFORMER-ERROR-HANDLING, indirect-api=false, port=P_CalDataProvider_Nvm_SVSCamOCCalibData
        enable-take-address=false, error-handling=NO-TRANSFORMER-ERROR-HANDLING, indirect-api=false, port=P_CalDataProvider_Nvm_SVSCamSCCalibData
      8 x runnable:
        RE_Periodic_CalDataProvider  # Periodic Runnable of Satellite
          data-receive-point-by-arguments:
            18 x access:
              REC_R_CalDataProvider_Nvm_SVSCamCurrentCalibData_TbSVS_S_SVSCamCurrentCalibDataToNVM_t: accessed-variable=R_CalDataProvider_Nvm_SVSCamCurrentCalibData.TbSVS_S_SVSCamCurrentCalibDataToNVM_t
              REC_R_CalDataProvider_Nvm_SVSCamEOLCalibData_TbSVS_S_SVSCamEOLCalibDataToNVM_t: accessed-variable=R_CalDataProvider_Nvm_SVSCamEOLCalibData.TbSVS_S_SVSCamEOLCalibDataToNVM_t
              REC_R_CalDataProvider_Nvm_SVSCamOCCalibData_TbSVS_S_SVSCamOCCalibDataToNVM_t: accessed-variable=R_CalDataProvider_Nvm_SVSCamOCCalibData.TbSVS_S_SVSCamOCCalibDataToNVM_t
              REC_R_CalDataProvider_Nvm_SVSCamSCCalibData_TbSVS_S_SVSCamSCCalibDataToNVM_t: accessed-variable=R_CalDataProvider_Nvm_SVSCamSCCalibData.TbSVS_S_SVSCamSCCalibDataToNVM_t
              REC_R_SSM_QNXState_State_QNX: accessed-variable=R_SSM_QNXState.State_QNX
              REC_R_SSM_2_State_State_2_0: accessed-variable=R_SSM_2_State.State_2_0
              REC_R_SSM_2_State_State_2_1: accessed-variable=R_SSM_2_State.State_2_1
              REC_R_SSM_1_0_State_State_1_0: accessed-variable=R_SSM_1_0_State.State_1_0
              REC_RpVariantData_Variant: accessed-variable=RpVariantData.Variant
              REC_RpToSwcFD02Rx_TotalOdometer: accessed-variable=RpToSwcFD02Rx.TotalOdometer
              REC_RpCamEepromData_Svs_CamEepromDataArray_t: accessed-variable=RpCamEepromData.Svs_CamEepromDataArray_t
              REC_RpMEProxi_ME_Proxi_MPU1_0_to_MCU1_0_t: accessed-variable=RpMEProxi.ME_Proxi_MPU1_0_to_MCU1_0_t
              REC_RpProxiToSWC_SurroundViewCam_u8: accessed-variable=RpProxiToSWC.SurroundViewCam_u8
              REC_RpCalibRoutineTrigger_routine_b: accessed-variable=RpCalibRoutineTrigger.routine_b
              REC_R_SystemState_SystemState: accessed-variable=R_SystemState.SystemState
              REC_RpResetNvmFlag_V_ResetNvmFlag_b: accessed-variable=RpResetNvmFlag.V_ResetNvmFlag_b
              REC_Rp_PlantOdoData_PlantOdoData: accessed-variable=Rp_PlantOdoData.PlantOdoData
              REC_RpCalibRoutineType_value: accessed-variable=RpCalibRoutineType.value
          data-send-points:
            4 x access:
              SEND_P_CalDataProvider_MCU1_0_Nvm_Data_CalData_mcu1_0: accessed-variable=P_CalDataProvider_MCU1_0_Nvm_Data.CalData_mcu1_0
              SEND_PpAPVarTunParam_TbAP_VrntTunParam_t: accessed-variable=PpAPVarTunParam.TbAP_VrntTunParam_t
              SEND_P_Request_BswM_ScCalStatus_requestedMode: accessed-variable=P_Request_BswM_ScCalStatus.requestedMode
              SEND_PpPreviousCamData_Data: accessed-variable=PpPreviousCamData.Data
          23 x sync call:
            SC_R_IPC_IPC_Write_v: operation=R_IPC.IPC_Write_v
            SC_R_CalDataProvider_ErrorMgrSat_1_0_QM_Error_CS_ReportErrorStatus1_0_QM: operation=R_CalDataProvider_ErrorMgrSat_1_0_QM_Error_CS.ReportErrorStatus1_0_QM
            SC_NvMService_AC3_SRBS_SVSCamCurrentCalibData_WriteBlock: operation=NvMService_AC3_SRBS_SVSCamCurrentCalibData.WriteBlock
            SC_NvMService_AC3_SRBS_SVSCamEOLCalibData_WriteBlock: operation=NvMService_AC3_SRBS_SVSCamEOLCalibData.WriteBlock
            SC_NvMService_AC3_SRBS_SVSCamOCCalibData_WriteBlock: operation=NvMService_AC3_SRBS_SVSCamOCCalibData.WriteBlock
            SC_NvMService_AC3_SRBS_SVSCamSCCalibData_WriteBlock: operation=NvMService_AC3_SRBS_SVSCamSCCalibData.WriteBlock
            SC_RpError_CS_B_ReportErrorStatus1_0_B: operation=RpError_CS_B.ReportErrorStatus1_0_B
            SC_NvMService_AC3_SRBS_FrontCamSerialNumber_WriteBlock: operation=NvMService_AC3_SRBS_FrontCamSerialNumber.WriteBlock
            SC_NvMService_AC3_SRBS_LeftCamSerialNumber_WriteBlock: operation=NvMService_AC3_SRBS_LeftCamSerialNumber.WriteBlock
            SC_NvMService_AC3_SRBS_RearCamSerialNumber_WriteBlock: operation=NvMService_AC3_SRBS_RearCamSerialNumber.WriteBlock
            SC_NvMService_AC3_SRBS_RightCamSerialNumber_WriteBlock: operation=NvMService_AC3_SRBS_RightCamSerialNumber.WriteBlock
            SC_NvMService_AC3_SRBS_FrontCamSerialNumber_GetErrorStatus: operation=NvMService_AC3_SRBS_FrontCamSerialNumber.GetErrorStatus
            SC_NvMService_AC3_SRBS_LeftCamSerialNumber_GetErrorStatus: operation=NvMService_AC3_SRBS_LeftCamSerialNumber.GetErrorStatus
            SC_NvMService_AC3_SRBS_RearCamSerialNumber_GetErrorStatus: operation=NvMService_AC3_SRBS_RearCamSerialNumber.GetErrorStatus
            SC_NvMService_AC3_SRBS_RightCamSerialNumber_GetErrorStatus: operation=NvMService_AC3_SRBS_RightCamSerialNumber.GetErrorStatus
            SC_NvMService_AC3_SRBS_SVSCamCurrentCalibData_GetErrorStatus: operation=NvMService_AC3_SRBS_SVSCamCurrentCalibData.GetErrorStatus
            SC_NvMService_AC3_SRBS_SVSCamEOLCalibData_GetErrorStatus: operation=NvMService_AC3_SRBS_SVSCamEOLCalibData.GetErrorStatus
            SC_NvMService_AC3_SRBS_SVSCamOCCalibData_GetErrorStatus: operation=NvMService_AC3_SRBS_SVSCamOCCalibData.GetErrorStatus
            SC_NvMService_AC3_SRBS_SVSCamSCCalibData_GetErrorStatus: operation=NvMService_AC3_SRBS_SVSCamSCCalibData.GetErrorStatus
            SC_NvMService_AC3_SRBS_FrontCamSerialNumber_ReadBlock: operation=NvMService_AC3_SRBS_FrontCamSerialNumber.ReadBlock
            SC_NvMService_AC3_SRBS_LeftCamSerialNumber_ReadBlock: operation=NvMService_AC3_SRBS_LeftCamSerialNumber.ReadBlock
            SC_NvMService_AC3_SRBS_RearCamSerialNumber_ReadBlock: operation=NvMService_AC3_SRBS_RearCamSerialNumber.ReadBlock
            SC_NvMService_AC3_SRBS_RightCamSerialNumber_ReadBlock: operation=NvMService_AC3_SRBS_RightCamSerialNumber.ReadBlock
        RE_CalDataProvider_Init
        RE_CalDataProvider_Nvm_SVSCamSCCalibData_WriteBlock
        RE_CalDataProvider_Nvm_SVSCamOCCalibData_WriteBlock
        RE_CalDataProvider_Nvm_SVSCamCurrentCalibData_WriteBlock
        RE_CalDataProvider_Nvm_SVSCamEOLCalibData_WriteBlock
        RE_CalDataProvider_Nvm_SVSCamCalibReset
        RE_IntrinsicCameraSN_Readblock
      8 x swc service dependency, all with category=SERVICE:
        SVSCamEOLCalibData: assigned-datas=role-based-data-assignment={role=defaultValue, used-parameter-element=SVSCamEOLCalibData_DefaultValue}, assigned-ports=role-based-port-assignment={port-prototype=NvMService_AC3_SRBS_SVSCamEOLCalibData, role=NvMService_AC3_SRBS}
          service-needs:
            nv block needs SVSCamEOLCalibData: calc-ram-block-crc=true, check-static-block-id=false, n-data-sets=0, ram-block-status-control=API, readonly=false, reliability=ERROR-CORRECTION, resistant-to-changed-sw=true, restore-at-start=true, store-at-shutdown=false, store-cyclic=false, store-emergency=false, use-auto-validation-at-shut-down=false, use-crc-comp-mechanism=true, write-only-once=false, write-verification=false
        SVSCamSCCalibData: assigned-datas=role-based-data-assignment={role=defaultValue, used-parameter-element=SVSCamSCCalibData_DefaultValue}, assigned-ports=role-based-port-assignment={port-prototype=NvMService_AC3_SRBS_SVSCamSCCalibData, role=NvMService_AC3_SRBS}
          service-needs:
            nv block needs SVSCamSCCalibData: calc-ram-block-crc=true, check-static-block-id=false, n-data-sets=0, ram-block-status-control=API, readonly=false, reliability=ERROR-CORRECTION, resistant-to-changed-sw=true, restore-at-start=true, store-at-shutdown=false, store-cyclic=false, store-emergency=false, use-auto-validation-at-shut-down=false, use-crc-comp-mechanism=true, write-only-once=false, write-verification=false
        SVSCamOCCalibData: assigned-datas=role-based-data-assignment={role=defaultValue, used-parameter-element=SVSCamOCCalibData_DefaultValue}, assigned-ports=role-based-port-assignment={port-prototype=NvMService_AC3_SRBS_SVSCamOCCalibData, role=NvMService_AC3_SRBS}
          service-needs:
            nv block needs SVSCamOCCalibData: calc-ram-block-crc=true, check-static-block-id=false, n-data-sets=0, ram-block-status-control=API, readonly=false, reliability=ERROR-CORRECTION, resistant-to-changed-sw=true, restore-at-start=true, store-at-shutdown=false, store-cyclic=false, store-emergency=false, use-auto-validation-at-shut-down=false, use-crc-comp-mechanism=true, write-only-once=false, write-verification=false
        SVSCamCurrentCalibData: assigned-datas=role-based-data-assignment={role=defaultValue, used-parameter-element=SVSCamCurrentCalibData_DefaultValue}, assigned-ports=role-based-port-assignment={port-prototype=NvMService_AC3_SRBS_SVSCamCurrentCalibData, role=NvMService_AC3_SRBS}
          service-needs:
            nv block needs SVSCamCurrentCalibData: calc-ram-block-crc=true, check-static-block-id=false, n-data-sets=0, ram-block-status-control=API, readonly=false, reliability=ERROR-CORRECTION, resistant-to-changed-sw=true, restore-at-start=true, store-at-shutdown=false, store-cyclic=false, store-emergency=false, use-auto-validation-at-shut-down=false, use-crc-comp-mechanism=true, write-only-once=false, write-verification=false
        FrontCamSerialNumber: assigned-datas=role-based-data-assignment={role=defaultValue, used-parameter-element=FrontCamSerialNumber_DefaultValue}, assigned-ports=role-based-port-assignment={port-prototype=NvMService_AC3_SRBS_FrontCamSerialNumber, role=NvMService_AC3_SRBS}
          service-needs:
            nv block needs FrontCamSerialNumber: calc-ram-block-crc=true, check-static-block-id=false, n-data-sets=0, ram-block-status-control=API, readonly=false, reliability=ERROR-CORRECTION, resistant-to-changed-sw=true, restore-at-start=true, store-at-shutdown=false, store-cyclic=false, store-emergency=false, store-immediate=true, use-auto-validation-at-shut-down=false, use-crc-comp-mechanism=true, write-only-once=false, write-verification=false
        LeftCamSerialNumber: assigned-datas=role-based-data-assignment={role=defaultValue, used-parameter-element=LeftCamSerialNumber_DefaultValue}, assigned-ports=role-based-port-assignment={port-prototype=NvMService_AC3_SRBS_LeftCamSerialNumber, role=NvMService_AC3_SRBS}
          service-needs:
            nv block needs LeftCamSerialNumber: calc-ram-block-crc=true, check-static-block-id=false, n-data-sets=0, ram-block-status-control=API, readonly=false, reliability=ERROR-CORRECTION, resistant-to-changed-sw=true, restore-at-start=true, store-at-shutdown=false, store-cyclic=false, store-emergency=false, store-immediate=true, use-auto-validation-at-shut-down=false, use-crc-comp-mechanism=true, write-only-once=false, write-verification=false
        RearCamSerialNumber: assigned-datas=role-based-data-assignment={role=defaultValue, used-parameter-element=RearCamSerialNumber_DefaultValue}, assigned-ports=role-based-port-assignment={port-prototype=NvMService_AC3_SRBS_RearCamSerialNumber, role=NvMService_AC3_SRBS}
          service-needs:
            nv block needs RearCamSerialNumber: calc-ram-block-crc=true, check-static-block-id=false, n-data-sets=0, ram-block-status-control=API, readonly=false, reliability=ERROR-CORRECTION, resistant-to-changed-sw=true, restore-at-start=true, store-at-shutdown=false, store-cyclic=false, store-emergency=false, store-immediate=true, use-auto-validation-at-shut-down=false, use-crc-comp-mechanism=true, write-only-once=false, write-verification=false
        RightCamSerialNumber: assigned-datas=role-based-data-assignment={role=defaultValue, used-parameter-element=RightCamSerialNumber_DefaultValue}, assigned-ports=role-based-port-assignment={port-prototype=NvMService_AC3_SRBS_RightCamSerialNumber, role=NvMService_AC3_SRBS}
          service-needs:
            nv block needs RightCamSerialNumber: calc-ram-block-crc=true, check-static-block-id=false, n-data-sets=0, ram-block-status-control=API, readonly=false, reliability=ERROR-CORRECTION, resistant-to-changed-sw=true, restore-at-start=true, store-at-shutdown=false, store-cyclic=false, store-emergency=false, store-immediate=true, use-auto-validation-at-shut-down=false, use-crc-comp-mechanism=true, write-only-once=false, write-verification=false
  swc implementation CalDataProvider_Implementation: programming-language=C, vendor-id=0, behavior=CalDataProvider_InternalBehavior
    code-descriptors:
      code Default: artifact-descriptors=autosar-engineering-object=category=SWSRC
